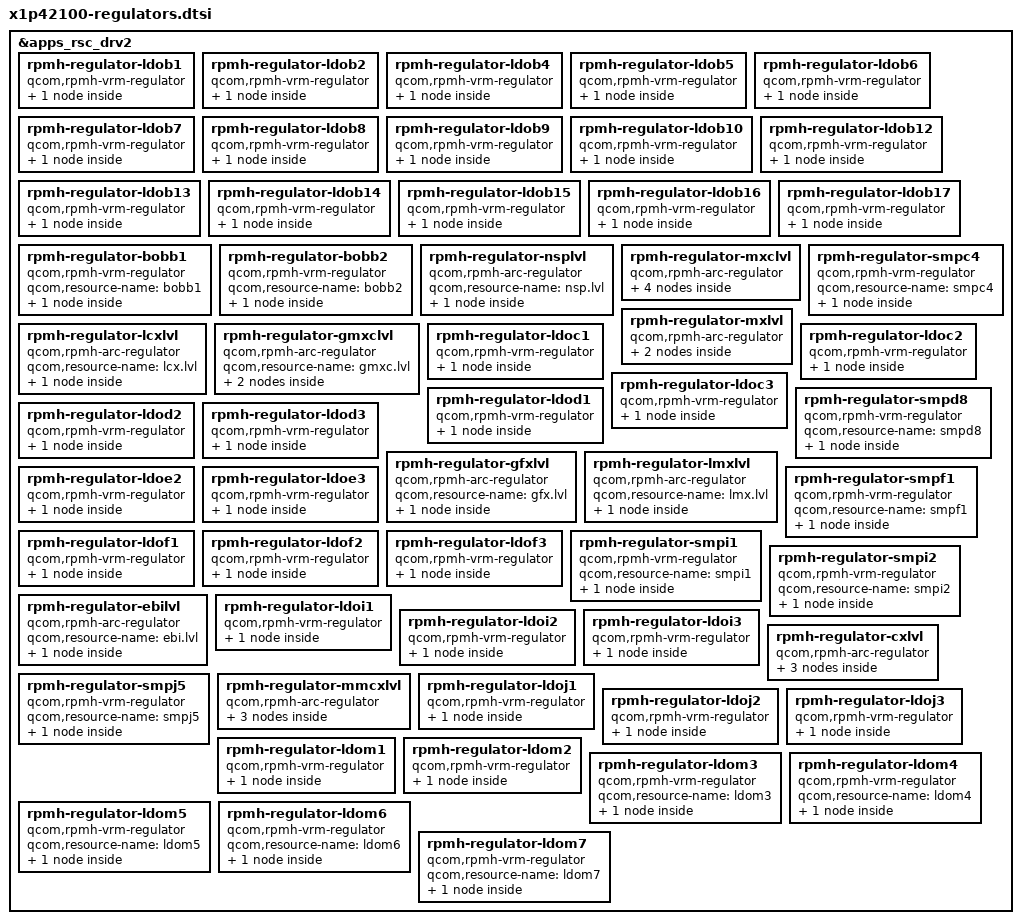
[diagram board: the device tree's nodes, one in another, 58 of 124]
// SPDX-License-Identifier: BSD-3-Clause
/*
 * Copyright (c) Qualcomm Technologies, Inc. and/or its subsidiaries.
 */

#include <dt-bindings/regulator/qcom,rpmh-regulator-levels.h>

&apps_rsc_drv2 {
	rpmh-regulator-ldob1 {
		compatible = "qcom,rpmh-vrm-regulator";
		qcom,resource-name = "ldob1";
		qcom,regulator-type = "pmic5-ldo";
		qcom,supported-modes =
			<RPMH_REGULATOR_MODE_LPM
			RPMH_REGULATOR_MODE_HPM>;
		qcom,mode-threshold-currents = <0 30000>;
		L1B:
		pm_humu_l1: regulator-pm-humu-l1 {
			regulator-name = "pm_humu_l1";
			qcom,set = <RPMH_REGULATOR_SET_ALL>;
			regulator-min-microvolt = <1800000>;
			regulator-max-microvolt = <1800000>;
			qcom,init-voltage = <1800000>;
			qcom,init-mode = <RPMH_REGULATOR_MODE_HPM>;
		};
	};

	rpmh-regulator-ldob2 {
		compatible = "qcom,rpmh-vrm-regulator";
		qcom,resource-name = "ldob2";
		qcom,regulator-type = "pmic5-ldo";
		qcom,supported-modes =
			<RPMH_REGULATOR_MODE_LPM
			RPMH_REGULATOR_MODE_HPM>;
		qcom,mode-threshold-currents = <0 10000>;
		L2B:
		pm_humu_l2: regulator-pm-humu-l2 {
			regulator-name = "pm_humu_l2";
			qcom,set = <RPMH_REGULATOR_SET_ALL>;
			regulator-min-microvolt = <3072000>;
			regulator-max-microvolt = <3100000>;
			qcom,init-voltage = <3072000>;
			qcom,init-mode = <RPMH_REGULATOR_MODE_HPM>;
		};
	};

	rpmh-regulator-ldob4 {
		compatible = "qcom,rpmh-vrm-regulator";
		qcom,resource-name = "ldob4";
		qcom,regulator-type = "pmic5-ldo";
		qcom,supported-modes =
			<RPMH_REGULATOR_MODE_LPM
			RPMH_REGULATOR_MODE_HPM>;
		qcom,mode-threshold-currents = <0 30000>;
		L4B:
		pm_humu_l4: regulator-pm-humu-l4 {
			regulator-name = "pm_humu_l4";
			qcom,set = <RPMH_REGULATOR_SET_ALL>;
			regulator-min-microvolt = <1800000>;
			regulator-max-microvolt = <1800000>;
			qcom,init-voltage = <1800000>;
			qcom,init-mode = <RPMH_REGULATOR_MODE_HPM>;
		};
	};

	rpmh-regulator-ldob5 {
		compatible = "qcom,rpmh-vrm-regulator";
		qcom,resource-name = "ldob5";
		qcom,regulator-type = "pmic5-ldo";
		qcom,supported-modes =
			<RPMH_REGULATOR_MODE_LPM
			RPMH_REGULATOR_MODE_HPM>;
		qcom,mode-threshold-currents = <0 10000>;
		L5B:
		pm_humu_l5: regulator-pm-humu-l5 {
			regulator-name = "pm_humu_l5";
			qcom,set = <RPMH_REGULATOR_SET_ALL>;
			regulator-min-microvolt = <3000000>;
			regulator-max-microvolt = <3000000>;
			qcom,init-voltage = <3000000>;
			qcom,init-mode = <RPMH_REGULATOR_MODE_HPM>;
		};
	};

	rpmh-regulator-ldob6 {
		compatible = "qcom,rpmh-vrm-regulator";
		qcom,resource-name = "ldob6";
		qcom,regulator-type = "pmic5-ldo";
		qcom,supported-modes =
			<RPMH_REGULATOR_MODE_LPM
			RPMH_REGULATOR_MODE_HPM>;
		qcom,mode-threshold-currents = <0 10000>;
		L6B:
		pm_humu_l6: regulator-pm-humu-l6 {
			regulator-name = "pm_humu_l6";
			qcom,set = <RPMH_REGULATOR_SET_ALL>;
			regulator-min-microvolt = <1800000>;
			regulator-max-microvolt = <2960000>;
			qcom,init-voltage = <1800000>;
			qcom,init-mode = <RPMH_REGULATOR_MODE_HPM>;
		};
	};

	rpmh-regulator-ldob7 {
		compatible = "qcom,rpmh-vrm-regulator";
		qcom,resource-name = "ldob7";
		qcom,regulator-type = "pmic5-ldo";
		qcom,supported-modes =
			<RPMH_REGULATOR_MODE_LPM
			RPMH_REGULATOR_MODE_HPM>;
		qcom,mode-threshold-currents = <0 10000>;
		L7B:
		pm_humu_l7: regulator-pm-humu-l7 {
			regulator-name = "pm_humu_l7";
			qcom,set = <RPMH_REGULATOR_SET_ALL>;
			regulator-min-microvolt = <2800000>;
			regulator-max-microvolt = <2800000>;
			qcom,init-voltage = <2800000>;
			qcom,init-mode = <RPMH_REGULATOR_MODE_HPM>;
		};
	};

	rpmh-regulator-ldob8 {
		compatible = "qcom,rpmh-vrm-regulator";
		qcom,resource-name = "ldob8";
		qcom,regulator-type = "pmic5-ldo";
		qcom,supported-modes =
			<RPMH_REGULATOR_MODE_LPM
			RPMH_REGULATOR_MODE_HPM>;
		qcom,mode-threshold-currents = <0 10000>;
		L8B:
		pm_humu_l8: regulator-pm-humu-l8 {
			regulator-name = "pm_humu_l8";
			qcom,set = <RPMH_REGULATOR_SET_ALL>;
			regulator-min-microvolt = <3072000>;
			regulator-max-microvolt = <3072000>;
			qcom,init-voltage = <3072000>;
			qcom,init-mode = <RPMH_REGULATOR_MODE_HPM>;
		};
	};

	rpmh-regulator-ldob9 {
		compatible = "qcom,rpmh-vrm-regulator";
		qcom,resource-name = "ldob9";
		qcom,regulator-type = "pmic5-ldo";
		qcom,supported-modes =
			<RPMH_REGULATOR_MODE_LPM
			RPMH_REGULATOR_MODE_HPM>;
		qcom,mode-threshold-currents = <0 10000>;
		L9B:
		pm_humu_l9: regulator-pm-humu-l9 {
			regulator-name = "pm_humu_l9";
			qcom,set = <RPMH_REGULATOR_SET_ALL>;
			regulator-min-microvolt = <2960000>;
			regulator-max-microvolt = <2960000>;
			qcom,init-voltage = <2960000>;
			qcom,init-mode = <RPMH_REGULATOR_MODE_HPM>;
		};
	};

	rpmh-regulator-ldob10 {
		compatible = "qcom,rpmh-vrm-regulator";
		qcom,resource-name = "ldob10";
		qcom,regulator-type = "pmic5-ldo";
		qcom,supported-modes =
			<RPMH_REGULATOR_MODE_LPM
			RPMH_REGULATOR_MODE_HPM>;
		qcom,mode-threshold-currents = <0 30000>;
		L10B:
		pm_humu_l10: regulator-pm-humu-l10 {
			regulator-name = "pm_humu_l10";
			qcom,set = <RPMH_REGULATOR_SET_ALL>;
			regulator-min-microvolt = <1800000>;
			regulator-max-microvolt = <1800000>;
			qcom,init-voltage = <1800000>;
			qcom,init-mode = <RPMH_REGULATOR_MODE_HPM>;
		};
	};

	rpmh-regulator-ldob12 {
		compatible = "qcom,rpmh-vrm-regulator";
		qcom,resource-name = "ldob12";
		qcom,regulator-type = "pmic5-ldo";
		qcom,supported-modes =
			<RPMH_REGULATOR_MODE_LPM
			RPMH_REGULATOR_MODE_HPM>;
		qcom,mode-threshold-currents = <0 30000>;
		L12B:
		pm_humu_l12: regulator-pm-humu-l12 {
			regulator-name = "pm_humu_l12";
			qcom,set = <RPMH_REGULATOR_SET_ALL>;
			regulator-min-microvolt = <1200000>;
			regulator-max-microvolt = <1200000>;
			qcom,init-voltage = <1200000>;
			qcom,init-mode = <RPMH_REGULATOR_MODE_HPM>;
		};
	};

	rpmh-regulator-ldob13 {
		compatible = "qcom,rpmh-vrm-regulator";
		qcom,resource-name = "ldob13";
		qcom,regulator-type = "pmic5-ldo";
		qcom,supported-modes =
			<RPMH_REGULATOR_MODE_LPM
			RPMH_REGULATOR_MODE_HPM>;
		qcom,mode-threshold-currents = <0 10000>;
		L13B:
		pm_humu_l13: regulator-pm-humu-l13 {
			regulator-name = "pm_humu_l13";
			qcom,set = <RPMH_REGULATOR_SET_ALL>;
			regulator-min-microvolt = <3072000>;
			regulator-max-microvolt = <3072000>;
			qcom,init-voltage = <3072000>;
			qcom,init-mode = <RPMH_REGULATOR_MODE_HPM>;
		};
	};

	rpmh-regulator-ldob14 {
		compatible = "qcom,rpmh-vrm-regulator";
		qcom,resource-name = "ldob14";
		qcom,regulator-type = "pmic5-ldo";
		qcom,supported-modes =
			<RPMH_REGULATOR_MODE_LPM
			RPMH_REGULATOR_MODE_HPM>;
		qcom,mode-threshold-currents = <0 10000>;
		L14B:
		pm_humu_l14: regulator-pm-humu-l14 {
			regulator-name = "pm_humu_l14";
			qcom,set = <RPMH_REGULATOR_SET_ALL>;
			regulator-min-microvolt = <3072000>;
			regulator-max-microvolt = <3072000>;
			qcom,init-voltage = <3072000>;
			qcom,init-mode = <RPMH_REGULATOR_MODE_HPM>;
		};
	};

	rpmh-regulator-ldob15 {
		compatible = "qcom,rpmh-vrm-regulator";
		qcom,resource-name = "ldob15";
		qcom,regulator-type = "pmic5-ldo";
		qcom,supported-modes =
			<RPMH_REGULATOR_MODE_LPM
			RPMH_REGULATOR_MODE_HPM>;
		qcom,mode-threshold-currents = <0 30000>;
		L15B:
		pm_humu_l15: regulator-pm-humu-l15 {
			regulator-name = "pm_humu_l15";
			qcom,set = <RPMH_REGULATOR_SET_ALL>;
			regulator-min-microvolt = <1800000>;
			regulator-max-microvolt = <1800000>;
			qcom,init-voltage = <1800000>;
			qcom,init-mode = <RPMH_REGULATOR_MODE_HPM>;
		};
	};

	rpmh-regulator-ldob16 {
		compatible = "qcom,rpmh-vrm-regulator";
		qcom,resource-name = "ldob16";
		qcom,regulator-type = "pmic5-ldo";
		qcom,supported-modes =
			<RPMH_REGULATOR_MODE_LPM
			RPMH_REGULATOR_MODE_HPM>;
		qcom,mode-threshold-currents = <0 10000>;
		L16B:
		pm_humu_l16: regulator-pm-humu-l16 {
			regulator-name = "pm_humu_l16";
			qcom,set = <RPMH_REGULATOR_SET_ALL>;
			regulator-min-microvolt = <2912000>;
			regulator-max-microvolt = <2912000>;
			qcom,init-voltage = <2912000>;
			qcom,init-mode = <RPMH_REGULATOR_MODE_HPM>;
		};
	};

	rpmh-regulator-ldob17 {
		compatible = "qcom,rpmh-vrm-regulator";
		qcom,resource-name = "ldob17";
		qcom,regulator-type = "pmic5-ldo";
		qcom,supported-modes =
			<RPMH_REGULATOR_MODE_LPM
			RPMH_REGULATOR_MODE_HPM>;
		qcom,mode-threshold-currents = <0 10000>;
		L17B:
		pm_humu_l17: regulator-pm-humu-l17 {
			regulator-name = "pm_humu_l17";
			qcom,set = <RPMH_REGULATOR_SET_ALL>;
			regulator-min-microvolt = <2504000>;
			regulator-max-microvolt = <2504000>;
			qcom,init-voltage = <2504000>;
			qcom,init-mode = <RPMH_REGULATOR_MODE_HPM>;
		};
	};

	rpmh-regulator-bobb1 {
		compatible = "qcom,rpmh-vrm-regulator";
		qcom,resource-name = "bobb1";

		BOB1:
		pm_humu_bob1: regulator-pm-humu-bob1 {
			regulator-name = "pm_humu_bob1";
			qcom,set = <RPMH_REGULATOR_SET_ALL>;
			regulator-min-microvolt = <3008000>;
			regulator-max-microvolt = <3960000>;
			qcom,init-voltage = <3008000>;
		};
	};

	rpmh-regulator-bobb2 {
		compatible = "qcom,rpmh-vrm-regulator";
		qcom,resource-name = "bobb2";

		BOB2:
		pm_humu_bob2: regulator-pm-humu-bob2 {
			regulator-name = "pm_humu_bob2";
			qcom,set = <RPMH_REGULATOR_SET_ALL>;
			regulator-min-microvolt = <2504000>;
			regulator-max-microvolt = <3008000>;
			qcom,init-voltage = <2504000>;
		};
	};

	rpmh-regulator-nsplvl {
		compatible = "qcom,rpmh-arc-regulator";
		qcom,resource-name = "nsp.lvl";
		VDD_NSP_LEVEL:
		S1C_LEVEL:
		pm_v8c_s1_level: regulator-pm-v8c-s1-level {
			regulator-name = "pm_v8c_s1_level";
			qcom,set = <RPMH_REGULATOR_SET_ALL>;
			regulator-min-microvolt =
				<RPMH_REGULATOR_LEVEL_RETENTION>;
			regulator-max-microvolt = <RPMH_REGULATOR_LEVEL_MAX>;
			qcom,init-voltage-level =
				<RPMH_REGULATOR_LEVEL_RETENTION>;
		};
	};

	rpmh-regulator-mxclvl {
		compatible = "qcom,rpmh-arc-regulator";
		qcom,resource-name = "mxc.lvl";
		proxy-supply = <&VDD_MXC_LEVEL>;

		VDD_MXC_LEVEL: S3C_LEVEL:
		pm_v8c_s3_level: regulator-pm-v8c-s3-level {
			regulator-name = "pm_v8c_s3_level";
			qcom,set = <RPMH_REGULATOR_SET_ALL>;
			regulator-min-microvolt =
				<RPMH_REGULATOR_LEVEL_RETENTION>;
			regulator-max-microvolt =
				<RPMH_REGULATOR_LEVEL_MAX>;
			qcom,init-voltage-level =
				<RPMH_REGULATOR_LEVEL_TURBO>;
			qcom,proxy-consumer-enable;
			qcom,proxy-consumer-voltage =
				<RPMH_REGULATOR_LEVEL_TURBO
				 RPMH_REGULATOR_LEVEL_MAX>;
		};

		VDD_MXC_LEVEL_AO: S3C_LEVEL_AO:
		pm_v8c_s3_level_ao: regulator-pm-v8c-s3-level-ao {
			regulator-name = "pm_v8c_s3_level_ao";
			qcom,set = <RPMH_REGULATOR_SET_ACTIVE>;
			regulator-min-microvolt =
				<RPMH_REGULATOR_LEVEL_RETENTION>;
			regulator-max-microvolt =
				<RPMH_REGULATOR_LEVEL_MAX>;
			qcom,init-voltage-level =
				<RPMH_REGULATOR_LEVEL_RETENTION>;
		};

		VDD_MXC_MMCX_VOTER_LEVEL: VDD_MXC_MM_VOTER_LEVEL:
		VDD_MM_MXC_VOTER_LEVEL: regulator-pm-v8c-s3-mmcx-voter-level {
			regulator-name = "pm_v8c_s3_mmcx_voter_level";
			pm_v8c_s3_mmcx_voter_level-parent-supply =
				<&VDD_MMCX_LEVEL>;
			qcom,set = <RPMH_REGULATOR_SET_ALL>;
			regulator-min-microvolt =
				<RPMH_REGULATOR_LEVEL_MIN_SVS>;
			regulator-max-microvolt =
				<RPMH_REGULATOR_LEVEL_MAX>;
			qcom,init-voltage-level =
				<RPMH_REGULATOR_LEVEL_MIN_SVS>;
		};

		VDD_MXC_GFX_VOTER_LEVEL: VDD_GFX_MXC_VOTER_LEVEL:
		regulator-pm-v8c-s3-gfx-voter-level {
			regulator-name = "pm_v8c_s3_gfx_voter_level";
			pm_v8c_s3_gfx_voter_level-parent-supply =
				<&VDD_GFX_LEVEL>;
			qcom,set = <RPMH_REGULATOR_SET_ALL>;
			regulator-min-microvolt =
				<RPMH_REGULATOR_LEVEL_MIN_SVS>;
			regulator-max-microvolt =
				<RPMH_REGULATOR_LEVEL_MAX>;
			qcom,init-voltage-level =
				<RPMH_REGULATOR_LEVEL_MIN_SVS>;
		};
	};

	rpmh-regulator-smpc4 {
		compatible = "qcom,rpmh-vrm-regulator";
		qcom,resource-name = "smpc4";
		S4C:
		pm_v8c_s4: regulator-pm-v8c-s4-level {
			regulator-name = "pm_v8c_s4";
			qcom,set = <RPMH_REGULATOR_SET_ALL>;
			regulator-min-microvolt = <1856000>;
			regulator-max-microvolt = <2000000>;
			qcom,init-voltage = <1856000>;
		};
	};

	rpmh-regulator-lcxlvl {
		compatible = "qcom,rpmh-arc-regulator";
		qcom,resource-name = "lcx.lvl";

		VDD_LPI_CX_LEVEL: S5C_LEVEL:
		pm_v8c_s5_level: regulator-pm-v8c-s5-level {
			regulator-name = "pm_v8c_s5_level";
			qcom,set = <RPMH_REGULATOR_SET_ALL>;
			regulator-min-microvolt =
				<RPMH_REGULATOR_LEVEL_RETENTION>;
			regulator-max-microvolt =
				<RPMH_REGULATOR_LEVEL_MAX>;
			qcom,init-voltage-level =
				<RPMH_REGULATOR_LEVEL_RETENTION>;
		};
	};

	rpmh-regulator-mxlvl {
		compatible = "qcom,rpmh-arc-regulator";
		qcom,resource-name = "mx.lvl";
		proxy-supply = <&VDD_MXA_LEVEL>;

		VDD_MXA_LEVEL: VDD_MX_LEVEL: S6C_LEVEL:
		pm_v8c_s6_level: regulator-pm-v8c-s6-level {
			regulator-name = "pm_v8c_s6_level";
			qcom,set = <RPMH_REGULATOR_SET_ALL>;
			regulator-min-microvolt =
				<RPMH_REGULATOR_LEVEL_RETENTION>;
			regulator-max-microvolt =
				<RPMH_REGULATOR_LEVEL_MAX>;
			qcom,init-voltage-level =
				<RPMH_REGULATOR_LEVEL_TURBO>;
			qcom,proxy-consumer-enable;
			qcom,proxy-consumer-voltage =
				<RPMH_REGULATOR_LEVEL_TURBO
				 RPMH_REGULATOR_LEVEL_MAX>;
		};

		VDD_MXA_LEVEL_AO: VDD_MX_LEVEL_AO: S6C_LEVEL_AO:
		pm_v8c_s6_level_ao: regulator-pm-v8c-s6-level-ao {
			regulator-name = "pm_v6f_s6_level_ao";
			qcom,set = <RPMH_REGULATOR_SET_ACTIVE>;
			regulator-min-microvolt =
				<RPMH_REGULATOR_LEVEL_RETENTION>;
			regulator-max-microvolt =
				<RPMH_REGULATOR_LEVEL_MAX>;
			qcom,init-voltage-level =
				<RPMH_REGULATOR_LEVEL_RETENTION>;
		};
	};

	rpmh-regulator-gmxclvl {
		compatible = "qcom,rpmh-arc-regulator";
		qcom,resource-name = "gmxc.lvl";

		VDD_GFX_MXC_LEVEL: S8C_LEVEL:
		pm_v8c_s8_level: regulator-pm-v8c-s8-level {
			regulator-name = "pm_v8c_s8_level";
			qcom,set = <RPMH_REGULATOR_SET_ALL>;
			regulator-min-microvolt =
				<RPMH_REGULATOR_LEVEL_RETENTION>;
			regulator-max-microvolt =
				<RPMH_REGULATOR_LEVEL_MAX>;
			qcom,init-voltage-level =
				<RPMH_REGULATOR_LEVEL_RETENTION>;
		};

		VDD_GFX_MXC_GFX_VOTER_LEVEL: VDD_GFX_GFX_MXC_VOTER_LEVEL:
		regulator-pm-v8c-s8-gfx-voter-level {
			regulator-name = "pm_v8c_s8_gfx_voter_level";
			pm_v8c_s8_gfx_voter_level-parent-supply =
				<&VDD_GFX_LEVEL>;
			qcom,set = <RPMH_REGULATOR_SET_ALL>;
			regulator-min-microvolt =
				<RPMH_REGULATOR_LEVEL_MIN_SVS>;
			regulator-max-microvolt =
				<RPMH_REGULATOR_LEVEL_MAX>;
			qcom,init-voltage-level =
				<RPMH_REGULATOR_LEVEL_MIN_SVS>;
		};
	};



	rpmh-regulator-ldoc1 {
		compatible = "qcom,rpmh-vrm-regulator";
		qcom,resource-name = "ldoc1";
		qcom,regulator-type = "pmic5-ldo";
		qcom,supported-modes =
			<RPMH_REGULATOR_MODE_LPM
			RPMH_REGULATOR_MODE_HPM>;
		qcom,mode-threshold-currents = <0 30000>;
		L1C:
		pm_v8c_l1: regulator-pm-v8c-l1 {
			regulator-name = "pm_v8c_l1";
			qcom,set = <RPMH_REGULATOR_SET_ALL>;
			regulator-min-microvolt = <1200000>;
			regulator-max-microvolt = <1200000>;
			qcom,init-voltage = <1200000>;
			qcom,init-mode = <RPMH_REGULATOR_MODE_HPM>;
		};
	};

	rpmh-regulator-ldoc2 {
		compatible = "qcom,rpmh-vrm-regulator";
		qcom,resource-name = "ldoc2";
		qcom,regulator-type = "pmic5-ldo";
		qcom,supported-modes =
			<RPMH_REGULATOR_MODE_LPM
			RPMH_REGULATOR_MODE_HPM>;
		qcom,mode-threshold-currents = <0 30000>;
		L2C:
		pm_v8c_l2: regulator-pm-v8c-l2 {
			regulator-name = "pm_v8c_l2";
			qcom,set = <RPMH_REGULATOR_SET_ALL>;
			regulator-min-microvolt = <880000>;
			regulator-max-microvolt = <920000>;
			qcom,init-voltage = <880000>;
			qcom,init-mode = <RPMH_REGULATOR_MODE_HPM>;
		};
	};

	rpmh-regulator-ldoc3 {
		compatible = "qcom,rpmh-vrm-regulator";
		qcom,resource-name = "ldoc3";
		qcom,regulator-type = "pmic5-ldo";
		qcom,supported-modes =
			<RPMH_REGULATOR_MODE_LPM
			RPMH_REGULATOR_MODE_HPM>;
		qcom,mode-threshold-currents = <0 30000>;
		L3C:
		pm_v8c_l3: regulator-pm-v8c-l3 {
			regulator-name = "pm_v8c_l3";
			qcom,set = <RPMH_REGULATOR_SET_ALL>;
			regulator-min-microvolt = <912000>;
			regulator-max-microvolt = <920000>;
			qcom,init-voltage = <912000>;
			qcom,init-mode = <RPMH_REGULATOR_MODE_HPM>;
		};
	};

	rpmh-regulator-smpd8 {
		compatible = "qcom,rpmh-vrm-regulator";
		qcom,resource-name = "smpd8";
		S8D:
		pmc8380d_s8: regulator-pmc8380d-s8 {
			regulator-name = "pmc8380d_s8";
			qcom,set = <RPMH_REGULATOR_SET_ALL>;
			regulator-min-microvolt = <300000>;
			regulator-max-microvolt = <700000>;
			qcom,init-voltage = <300000>;
		};
	};

	rpmh-regulator-ldod1 {
		compatible = "qcom,rpmh-vrm-regulator";
		qcom,resource-name = "ldod1";
		qcom,regulator-type = "pmic5-ldo";
		qcom,supported-modes =
			<RPMH_REGULATOR_MODE_LPM
			RPMH_REGULATOR_MODE_HPM>;
		qcom,mode-threshold-currents = <0 30000>;
		L1D:
		pmc8380d_l1: regulator-pmc8380d-l1 {
			regulator-name = "pmc8380d_l1";
			qcom,set = <RPMH_REGULATOR_SET_ALL>;
			regulator-min-microvolt = <880000>;
			regulator-max-microvolt = <920000>;
			qcom,init-voltage = <880000>;
			qcom,init-mode = <RPMH_REGULATOR_MODE_HPM>;
		};
	};

	rpmh-regulator-ldod2 {
		compatible = "qcom,rpmh-vrm-regulator";
		qcom,resource-name = "ldod2";
		qcom,regulator-type = "pmic5-ldo";
		qcom,supported-modes =
			<RPMH_REGULATOR_MODE_LPM
			RPMH_REGULATOR_MODE_HPM>;
		qcom,mode-threshold-currents = <0 30000>;
		L2D:
		pmc8380d_l2: regulator-pmc8380d-l2 {
			regulator-name = "pmc8380d_l2";
			qcom,set = <RPMH_REGULATOR_SET_ALL>;
			regulator-min-microvolt = <912000>;
			regulator-max-microvolt = <920000>;
			qcom,init-voltage = <912000>;
			qcom,init-mode = <RPMH_REGULATOR_MODE_HPM>;
		};
	};

	rpmh-regulator-ldod3 {
		compatible = "qcom,rpmh-vrm-regulator";
		qcom,resource-name = "ldod3";
		qcom,regulator-type = "pmic5-ldo";
		qcom,supported-modes =
			<RPMH_REGULATOR_MODE_LPM
			RPMH_REGULATOR_MODE_HPM>;
		qcom,mode-threshold-currents = <0 30000>;
		L3D:
		pmc8380d_l3: regulator-pmc8380d-l3 {
			regulator-name = "pmc8380d_l3";
			qcom,set = <RPMH_REGULATOR_SET_ALL>;
			regulator-min-microvolt = <1800000>;
			regulator-max-microvolt = <1800000>;
			qcom,init-voltage = <1800000>;
			qcom,init-mode = <RPMH_REGULATOR_MODE_HPM>;
		};
	};

	rpmh-regulator-gfxlvl {
		compatible = "qcom,rpmh-arc-regulator";
		qcom,resource-name = "gfx.lvl";

		VDD_GFX_LEVEL: S1E_LEVEL:
		pmc8380e_s1_level: regulator-pmc8380e-s1-level {
			regulator-name = "pmc8380e_s1_level";
			qcom,set = <RPMH_REGULATOR_SET_ALL>;
			regulator-min-microvolt =
				<RPMH_REGULATOR_LEVEL_RETENTION>;
			regulator-max-microvolt =
				<RPMH_REGULATOR_LEVEL_MAX>;
			qcom,init-voltage-level =
				<RPMH_REGULATOR_LEVEL_RETENTION>;
		};
	};

	rpmh-regulator-lmxlvl {
		compatible = "qcom,rpmh-arc-regulator";
		qcom,resource-name = "lmx.lvl";
		VDD_LPI_MX_LEVEL:
		L1E_LEVEL:
		pmc8380e_l1_level: regulator-pmc8380e-l1-level {
			regulator-name = "pmc8380e_l1_level";
			qcom,set = <RPMH_REGULATOR_SET_ALL>;
			regulator-min-microvolt =
				<RPMH_REGULATOR_LEVEL_RETENTION>;
			regulator-max-microvolt = <RPMH_REGULATOR_LEVEL_MAX>;
			qcom,init-voltage-level =
				<RPMH_REGULATOR_LEVEL_RETENTION>;
		};
	};

	rpmh-regulator-ldoe2 {
		compatible = "qcom,rpmh-vrm-regulator";
		qcom,resource-name = "ldoe2";
		qcom,regulator-type = "pmic5-ldo";
		qcom,supported-modes =
			<RPMH_REGULATOR_MODE_LPM
			RPMH_REGULATOR_MODE_HPM>;
		qcom,mode-threshold-currents = <0 30000>;
		L2E:
		pmc8380e_l2: regulator-pmc8380e-l2 {
			regulator-name = "pmc8380e_l2";
			qcom,set = <RPMH_REGULATOR_SET_ALL>;
			regulator-min-microvolt = <880000>;
			regulator-max-microvolt = <920000>;
			qcom,init-voltage = <880000>;
			qcom,init-mode = <RPMH_REGULATOR_MODE_HPM>;
		};
	};

	rpmh-regulator-ldoe3 {
		compatible = "qcom,rpmh-vrm-regulator";
		qcom,resource-name = "ldoe3";
		qcom,regulator-type = "pmic5-ldo";
		qcom,supported-modes =
			<RPMH_REGULATOR_MODE_LPM
			RPMH_REGULATOR_MODE_HPM>;
		qcom,mode-threshold-currents = <0 30000>;
		L3E:
		pmc8380e_l3: regulator-pmc8380e-l3 {
			regulator-name = "pmc8380e_l3";
			qcom,set = <RPMH_REGULATOR_SET_ALL>;
			regulator-min-microvolt = <1200000>;
			regulator-max-microvolt = <1200000>;
			qcom,init-voltage = <1200000>;
			qcom,init-mode = <RPMH_REGULATOR_MODE_HPM>;
		};
	};

	rpmh-regulator-smpf1 {
		compatible = "qcom,rpmh-vrm-regulator";
		qcom,resource-name = "smpf1";
		S1F:
		pmc8380f_s1: regulator-pmc8380f-s1 {
			regulator-name = "pmc8380f_s1";
			qcom,set = <RPMH_REGULATOR_SET_ALL>;
			regulator-min-microvolt = <700000>;
			regulator-max-microvolt = <1100000>;
			qcom,init-voltage = <700000>;
		};
	};

	rpmh-regulator-ldof1 {
		compatible = "qcom,rpmh-vrm-regulator";
		qcom,resource-name = "ldof1";
		qcom,regulator-type = "pmic5-ldo";
		qcom,supported-modes =
			<RPMH_REGULATOR_MODE_LPM
			RPMH_REGULATOR_MODE_HPM>;
		qcom,mode-threshold-currents = <0 30000>;
		L1F:
		pmc8380f_l1: regulator-pmc8380f-l1 {
			regulator-name = "pmc8380f_l1";
			qcom,set = <RPMH_REGULATOR_SET_ALL>;
			regulator-min-microvolt = <1024000>;
			regulator-max-microvolt = <1024000>;
			qcom,init-voltage = <1024000>;
			qcom,init-mode = <RPMH_REGULATOR_MODE_HPM>;
		};
	};

	rpmh-regulator-ldof2 {
		compatible = "qcom,rpmh-vrm-regulator";
		qcom,resource-name = "ldof2";
		qcom,regulator-type = "pmic5-ldo";
		qcom,supported-modes =
			<RPMH_REGULATOR_MODE_LPM
			RPMH_REGULATOR_MODE_HPM>;
		qcom,mode-threshold-currents = <0 30000>;
		L2F:
		pmc8380f_l2: regulator-pmc8380f-l2 {
			regulator-name = "pmc8380f_l2";
			qcom,set = <RPMH_REGULATOR_SET_ALL>;
			regulator-min-microvolt = <1024000>;
			regulator-max-microvolt = <1024000>;
			qcom,init-voltage = <1024000>;
			qcom,init-mode = <RPMH_REGULATOR_MODE_HPM>;
		};
	};

	rpmh-regulator-ldof3 {
		compatible = "qcom,rpmh-vrm-regulator";
		qcom,resource-name = "ldof3";
		qcom,regulator-type = "pmic5-ldo";
		qcom,supported-modes =
			<RPMH_REGULATOR_MODE_LPM
			RPMH_REGULATOR_MODE_HPM>;
		qcom,mode-threshold-currents = <0 30000>;
		L3F:
		pmc8380f_l3: regulator-pmc8380f-l3 {
			regulator-name = "pmc8380f_l3";
			qcom,set = <RPMH_REGULATOR_SET_ALL>;
			regulator-min-microvolt = <1024000>;
			regulator-max-microvolt = <1024000>;
			qcom,init-voltage = <1024000>;
			qcom,init-mode = <RPMH_REGULATOR_MODE_HPM>;
		};
	};

	rpmh-regulator-smpi1 {
		compatible = "qcom,rpmh-vrm-regulator";
		qcom,resource-name = "smpi1";
		S1I:
		pm_v8i_s1: regulator-pm_v8i-s1 {
			regulator-name = "pm_v8i_s1";
			qcom,set = <RPMH_REGULATOR_SET_ALL>;
			regulator-min-microvolt = <900000>;
			regulator-max-microvolt = <920000>;
			qcom,init-voltage = <900000>;
		};
	};

	rpmh-regulator-smpi2 {
		compatible = "qcom,rpmh-vrm-regulator";
		qcom,resource-name = "smpi2";
		S2I:
		pm_v8i_s2: regulator-pm_v8i-s2 {
			regulator-name = "pm_v8i_s2";
			qcom,set = <RPMH_REGULATOR_SET_ALL>;
			regulator-min-microvolt = <1000000>;
			regulator-max-microvolt = <1100000>;
			qcom,init-voltage = <1000000>;
		};
	};

	rpmh-regulator-ebilvl {
		compatible = "qcom,rpmh-arc-regulator";
		qcom,resource-name = "ebi.lvl";

		VDD_EBI_LEVEL: VDD_EBI_A_LEVEL: S4I_LEVEL:
		pm_v8i_s4_level: regulator-pm-v8i-s4-level {
			regulator-name = "pm_v8i_s4_level";
			qcom,set = <RPMH_REGULATOR_SET_ALL>;
			regulator-min-microvolt =
				<RPMH_REGULATOR_LEVEL_RETENTION>;
			regulator-max-microvolt =
				<RPMH_REGULATOR_LEVEL_MAX>;
			qcom,init-voltage-level =
				<RPMH_REGULATOR_LEVEL_RETENTION>;
		};
	};

	rpmh-regulator-ldoi1 {
		compatible = "qcom,rpmh-vrm-regulator";
		qcom,resource-name = "ldoi1";
		qcom,regulator-type = "pmic5-ldo";
		qcom,supported-modes =
			<RPMH_REGULATOR_MODE_LPM
			RPMH_REGULATOR_MODE_HPM>;
		qcom,mode-threshold-currents = <0 30000>;
		L1I:
		pm_v8i_l1: regulator-pm_v8i-l1 {
			regulator-name = "pm_v8i_l1";
			qcom,set = <RPMH_REGULATOR_SET_ALL>;
			regulator-min-microvolt = <1800000>;
			regulator-max-microvolt = <1800000>;
			qcom,init-voltage = <1800000>;
			qcom,init-mode = <RPMH_REGULATOR_MODE_HPM>;
		};
	};

	rpmh-regulator-ldoi2 {
		compatible = "qcom,rpmh-vrm-regulator";
		qcom,resource-name = "ldoi2";
		qcom,regulator-type = "pmic5-ldo";
		qcom,supported-modes =
			<RPMH_REGULATOR_MODE_LPM
			RPMH_REGULATOR_MODE_HPM>;
		qcom,mode-threshold-currents = <0 30000>;
		L2I:
		pm_v8i_l2: regulator-pm_v8i-l2 {
			regulator-name = "pm_v8i_l2";
			qcom,set = <RPMH_REGULATOR_SET_ALL>;
			regulator-min-microvolt = <1200000>;
			regulator-max-microvolt = <1200000>;
			qcom,init-voltage = <1200000>;
			qcom,init-mode = <RPMH_REGULATOR_MODE_HPM>;
		};
	};

	rpmh-regulator-ldoi3 {
		compatible = "qcom,rpmh-vrm-regulator";
		qcom,resource-name = "ldoi3";
		qcom,regulator-type = "pmic5-ldo";
		qcom,supported-modes =
			<RPMH_REGULATOR_MODE_LPM
			RPMH_REGULATOR_MODE_HPM>;
		qcom,mode-threshold-currents = <0 30000>;
		L3I:
		pm_v8i_l3: regulator-pm_v8i-l3 {
			regulator-name = "pm_v8i_l3";
			qcom,set = <RPMH_REGULATOR_SET_ALL>;
			regulator-min-microvolt = <880000>;
			regulator-max-microvolt = <920000>;
			qcom,init-voltage = <880000>;
			qcom,init-mode = <RPMH_REGULATOR_MODE_HPM>;
		};
	};

	rpmh-regulator-cxlvl {
		compatible = "qcom,rpmh-arc-regulator";
		qcom,resource-name = "cx.lvl";
		proxy-supply = <&VDD_CX_LEVEL>;

		VDD_CX_LEVEL: S1J_LEVEL:
		pm_v8j_s1_level: regulator-pm-v8j-s1-level {
			regulator-name = "pm_v8j_s1_level";
			qcom,set = <RPMH_REGULATOR_SET_ALL>;
			regulator-min-microvolt =
				<RPMH_REGULATOR_LEVEL_RETENTION>;
			regulator-max-microvolt =
				<RPMH_REGULATOR_LEVEL_MAX>;
			qcom,init-voltage-level =
				<RPMH_REGULATOR_LEVEL_TURBO>;
			qcom,proxy-consumer-enable;
			qcom,proxy-consumer-voltage =
				<RPMH_REGULATOR_LEVEL_TURBO
				 RPMH_REGULATOR_LEVEL_MAX>;
		};

		VDD_CX_LEVEL_AO: S1J_LEVEL_AO:
		pm_v8j_s1_level_ao: regulator-pm-v8j-s1-level-ao {
			regulator-name = "pm_v8j_s1_level_ao";
			qcom,set = <RPMH_REGULATOR_SET_ACTIVE>;
			regulator-min-microvolt =
				<RPMH_REGULATOR_LEVEL_RETENTION>;
			regulator-max-microvolt =
				<RPMH_REGULATOR_LEVEL_MAX>;
			qcom,init-voltage-level =
				<RPMH_REGULATOR_LEVEL_RETENTION>;
		};

		VDD_CX_MMCX_SUPPLY_LEVEL: regulator-pm-v8j-s1-mmcx-sup-level {
			regulator-name = "pm_v8j_s1_mmcx_sup_level";
			qcom,set = <RPMH_REGULATOR_SET_ALL>;
			regulator-min-microvolt =
				<RPMH_REGULATOR_LEVEL_MIN_SVS>;
			regulator-max-microvolt =
				<RPMH_REGULATOR_LEVEL_MAX>;
			qcom,init-voltage-level =
				<RPMH_REGULATOR_LEVEL_MIN_SVS>;
		};
	};

	rpmh-regulator-smpj5 {
		compatible = "qcom,rpmh-vrm-regulator";
		qcom,resource-name = "smpj5";
		S5J:
		pm_v8j_s5: regulator-pm_v8j-s5 {
			regulator-name = "pm_v8j_s5";
			qcom,set = <RPMH_REGULATOR_SET_ALL>;
			regulator-min-microvolt = <1256000>;
			regulator-max-microvolt = <1304000>;
			qcom,init-voltage = <1256000>;
		};
	};

	rpmh-regulator-mmcxlvl {
		compatible = "qcom,rpmh-arc-regulator";
		qcom,resource-name = "mmcx.lvl";
		proxy-supply = <&VDD_MMCX_LEVEL>;

		VDD_MMCX_LEVEL: VDD_MM_LEVEL: S6J_LEVEL:
		pm_v8j_s6_level: regulator-pm-v8j-s6-level {
			regulator-name = "pm_v8j_s6_level";
			qcom,set = <RPMH_REGULATOR_SET_ALL>;
			pm_v8i_s3_level-parent-supply =
				<&VDD_CX_MMCX_SUPPLY_LEVEL>;
			regulator-min-microvolt =
				<RPMH_REGULATOR_LEVEL_LOW_SVS_D1>;
			regulator-max-microvolt =
				<RPMH_REGULATOR_LEVEL_MAX>;
			qcom,init-voltage-level =
				<RPMH_REGULATOR_LEVEL_TURBO>;
			qcom,proxy-consumer-enable;
			qcom,proxy-consumer-voltage =
				<RPMH_REGULATOR_LEVEL_TURBO
				 RPMH_REGULATOR_LEVEL_MAX>;
		};

		VDD_MMCX_LEVEL_AO: VDD_MM_LEVEL_AO: S6J_LEVEL_AO:
		pm_v8j_s6_level_ao: regulator-pm-v8j-s6-level-ao {
			regulator-name = "pm_v8j_s6_level_ao";
			qcom,set = <RPMH_REGULATOR_SET_ACTIVE>;
			regulator-min-microvolt =
				<RPMH_REGULATOR_LEVEL_LOW_SVS_D1>;
			regulator-max-microvolt =
				<RPMH_REGULATOR_LEVEL_MAX>;
			qcom,init-voltage-level =
				<RPMH_REGULATOR_LEVEL_LOW_SVS_D1>;
		};

		regulator-pm-v8j-s6-level-so {
			regulator-name = "pm_v8j_s6_level_so";
			qcom,set = <RPMH_REGULATOR_SET_SLEEP>;
			regulator-min-microvolt =
				<RPMH_REGULATOR_LEVEL_LOW_SVS_D1>;
			regulator-max-microvolt =
				<RPMH_REGULATOR_LEVEL_MAX>;
			qcom,init-voltage-level =
				<RPMH_REGULATOR_LEVEL_LOW_SVS_D1>;
		};
	};

	rpmh-regulator-ldoj1 {
		compatible = "qcom,rpmh-vrm-regulator";
		qcom,resource-name = "ldoj1";
		qcom,regulator-type = "pmic5-ldo";
		qcom,supported-modes =
			<RPMH_REGULATOR_MODE_LPM
			RPMH_REGULATOR_MODE_HPM>;
		qcom,mode-threshold-currents = <0 30000>;
		L1J:
		pm_v8j_l1: regulator-pm_v8j-l1 {
			regulator-name = "pm_v8j_l1";
			qcom,set = <RPMH_REGULATOR_SET_ALL>;
			regulator-min-microvolt = <912000>;
			regulator-max-microvolt = <920000>;
			qcom,init-voltage = <912000>;
			qcom,init-mode = <RPMH_REGULATOR_MODE_HPM>;
		};
	};

	rpmh-regulator-ldoj2 {
		compatible = "qcom,rpmh-vrm-regulator";
		qcom,resource-name = "ldoj2";
		qcom,regulator-type = "pmic5-ldo";
		qcom,supported-modes =
			<RPMH_REGULATOR_MODE_LPM
			RPMH_REGULATOR_MODE_HPM>;
		qcom,mode-threshold-currents = <0 30000>;
		L2J:
		pm_v8j_l2: regulator-pm_v8j-l2 {
			regulator-name = "pm_v8j_l2";
			qcom,set = <RPMH_REGULATOR_SET_ALL>;
			regulator-min-microvolt = <1256000>;
			regulator-max-microvolt = <1256000>;
			qcom,init-voltage = <1256000>;
			qcom,init-mode = <RPMH_REGULATOR_MODE_HPM>;
		};
	};

	rpmh-regulator-ldoj3 {
		compatible = "qcom,rpmh-vrm-regulator";
		qcom,resource-name = "ldoj3";
		qcom,regulator-type = "pmic5-ldo";
		qcom,supported-modes =
			<RPMH_REGULATOR_MODE_LPM
			RPMH_REGULATOR_MODE_HPM>;
		qcom,mode-threshold-currents = <0 30000>;
		L3J:
		pm_v8j_l3: regulator-pm_v8j-l3 {
			regulator-name = "pm_v8j_l3";
			qcom,set = <RPMH_REGULATOR_SET_ALL>;
			regulator-min-microvolt = <880000>;
			regulator-max-microvolt = <920000>;
			qcom,init-voltage = <880000>;
			qcom,init-mode = <RPMH_REGULATOR_MODE_HPM>;
		};
	};

	rpmh-regulator-ldom1 {
		compatible = "qcom,rpmh-vrm-regulator";
		qcom,resource-name = "ldom1";
		qcom,regulator-type = "pmic5-ldo";
		qcom,supported-modes =
			<RPMH_REGULATOR_MODE_LPM
			RPMH_REGULATOR_MODE_HPM>;
		qcom,mode-threshold-currents = <0 30000>;
		L1M:
		pm8010m_l1: regulator-pm8010m-l1 {
			regulator-name = "pm8010m_l1";
			qcom,set = <RPMH_REGULATOR_SET_ALL>;
			regulator-min-microvolt = <1056000>;
			regulator-max-microvolt = <1200000>;
			qcom,init-voltage = <1056000>;
			qcom,init-mode = <RPMH_REGULATOR_MODE_HPM>;
		};
	};

	rpmh-regulator-ldom2 {
		compatible = "qcom,rpmh-vrm-regulator";
		qcom,resource-name = "ldom2";
		qcom,regulator-type = "pmic5-ldo";
		qcom,supported-modes =
			<RPMH_REGULATOR_MODE_LPM
			RPMH_REGULATOR_MODE_HPM>;
		qcom,mode-threshold-currents = <0 30000>;
		L2M:
		pm8010m_l2: regulator-pm8010m-l2 {
			regulator-name = "pm8010m_l2";
			qcom,set = <RPMH_REGULATOR_SET_ALL>;
			regulator-min-microvolt = <1152000>;
			regulator-max-microvolt = <1200000>;
			qcom,init-voltage = <1152000>;
			qcom,init-mode = <RPMH_REGULATOR_MODE_HPM>;
		};
	};

	rpmh-regulator-ldom3 {
		compatible = "qcom,rpmh-vrm-regulator";
		qcom,resource-name = "ldom3";

		L3M:
		pm8010m_l3: regulator-pm8010m-l3 {
			regulator-name = "pm8010m_l3";
			qcom,set = <RPMH_REGULATOR_SET_ALL>;
			regulator-min-microvolt = <1808000>;
			regulator-max-microvolt = <1808000>;
			qcom,init-voltage = <1808000>;
		};
	};

	rpmh-regulator-ldom4 {
		compatible = "qcom,rpmh-vrm-regulator";
		qcom,resource-name = "ldom4";

		L4M:
		pm8010m_l4: regulator-pm8010m-l4 {
			regulator-name = "pm8010m_l4";
			qcom,set = <RPMH_REGULATOR_SET_ALL>;
			regulator-min-microvolt = <1808000>;
			regulator-max-microvolt = <1808000>;
			qcom,init-voltage = <1808000>;
		};
	};

	rpmh-regulator-ldom5 {
		compatible = "qcom,rpmh-vrm-regulator";
		qcom,resource-name = "ldom5";

		L5M:
		pm8010m_l5: regulator-pm8010m-l5 {
			regulator-name = "pm8010m_l5";
			qcom,set = <RPMH_REGULATOR_SET_ALL>;
			regulator-min-microvolt = <2960000>;
			regulator-max-microvolt = <2960000>;
			qcom,init-voltage = <2960000>;
		};
	};

	rpmh-regulator-ldom6 {
		compatible = "qcom,rpmh-vrm-regulator";
		qcom,resource-name = "ldom6";

		L6M:
		pm8010m_l6: regulator-pm8010m-l6 {
			regulator-name = "pm8010m_l6";
			qcom,set = <RPMH_REGULATOR_SET_ALL>;
			regulator-min-microvolt = <1808000>;
			regulator-max-microvolt = <1808000>;
			qcom,init-voltage = <1808000>;
		};
	};

	rpmh-regulator-ldom7 {
		compatible = "qcom,rpmh-vrm-regulator";
		qcom,resource-name = "ldom7";

		L7M:
		pm8010m_l7: regulator-pm8010m-l7 {
			regulator-name = "pm8010m_l7";
			qcom,set = <RPMH_REGULATOR_SET_ALL>;
			regulator-min-microvolt = <2912000>;
			regulator-max-microvolt = <2912000>;
			qcom,init-voltage = <2912000>;
		};
	};

};
